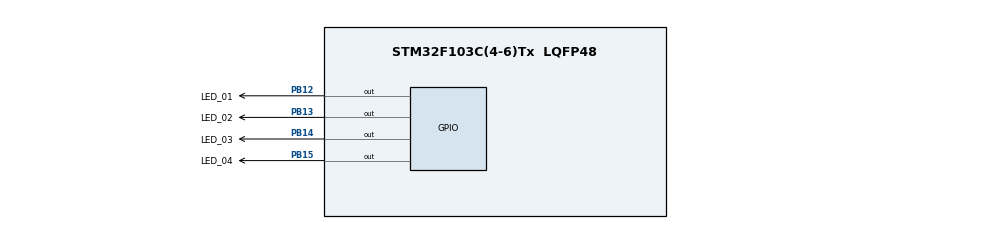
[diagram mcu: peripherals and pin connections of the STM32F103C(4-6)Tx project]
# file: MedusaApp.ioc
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Mcu.Family=STM32F1
Mcu.Name=STM32F103C(4-6)Tx
Mcu.Package=LQFP48
NVIC.PriorityGroup=NVIC_PRIORITYGROUP_4
NVIC.TIM1_UP_IRQn=true\:0\:0\:false\:false\:true\:true\:true
PA13.Mode=Serial_Wire
PA13.Signal=SYS_JTMS-SWDIO
PA14.Mode=Serial_Wire
PA14.Signal=SYS_JTCK-SWCLK
PB12.GPIO_Label=LED_01
PB12.Signal=GPIO_Output
PB13.GPIO_Label=LED_02
PB13.Signal=GPIO_Output
PB14.GPIO_Label=LED_03
PB14.Signal=GPIO_Output
PB15.GPIO_Label=LED_04
PB15.Signal=GPIO_Output
PC14-OSC32_IN.Mode=LSE-External-Oscillator
PC14-OSC32_IN.Signal=RCC_OSC32_IN
PC15-OSC32_OUT.Mode=LSE-External-Oscillator
PC15-OSC32_OUT.Signal=RCC_OSC32_OUT
ProjectManager.HeapSize=0x200
ProjectManager.StackSize=0x400
ProjectManager.TargetToolchain=STM32CubeIDE
RCC.APB1Freq_Value=8000000
RCC.APB2Freq_Value=8000000
TIM1.AutoReloadPreload=TIM_AUTORELOAD_PRELOAD_ENABLE
TIM1.Period=800
TIM1.Prescaler=1000
TIM1.TIM_MasterOutputTrigger=TIM_TRGO_UPDATE
VP_TIM1_VS_ClockSourceINT.Mode=Internal
board=custom

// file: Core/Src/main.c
/* USER CODE BEGIN Header */
/**
  ******************************************************************************
  * @file           : main.c
  * @brief          : Main program body
  ******************************************************************************
  * @attention
  *
  * <h2><center>&copy; Copyright (c) 2021 STMicroelectronics.
  * All rights reserved.</center></h2>
  *
  * This software component is licensed by ST under BSD 3-Clause license,
  * the "License"; You may not use this file except in compliance with the
  * License. You may obtain a copy of the License at:
  *                        opensource.org/licenses/BSD-3-Clause
  *
  * written date: 04/06/2021
  * revision number: SV 1.001
  ******************************************************************************
  */
/* USER CODE END Header */
#include "main.h"

TIM_HandleTypeDef htim1;

void SystemClock_Config(void);
static void MX_GPIO_Init(void);
static void MX_TIM1_Init(void);

int main(void)
{

  /* MCU Configuration--------------------------------------------------------*/

  /* Reset of all peripherals, Initializes the Flash interface and the Systick. */
  HAL_Init();

  /* Configure the system clock */
  SystemClock_Config();

  /* Initialize all configured peripherals */
  MX_GPIO_Init();
  MX_TIM1_Init();

  /* USER CODE BEGIN 2 */
  HAL_TIM_Base_Start_IT(&htim1);
  /* USER CODE END 2 */

  /* Infinite loop */
  /* USER CODE BEGIN WHILE */
  while (1)
  {
	  HAL_GPIO_TogglePin(LED_01_GPIO_Port, LED_01_Pin);
	  HAL_Delay(100);
    /* USER CODE END WHILE */

  }
}

void SystemClock_Config(void)
{
  RCC_OscInitTypeDef RCC_OscInitStruct = {0};
  RCC_ClkInitTypeDef RCC_ClkInitStruct = {0};

  /** Initializes the RCC Oscillators according to the specified parameters
  * in the RCC_OscInitTypeDef structure.
  */
  RCC_OscInitStruct.OscillatorType = RCC_OSCILLATORTYPE_HSI;
  RCC_OscInitStruct.HSIState = RCC_HSI_ON;
  RCC_OscInitStruct.HSICalibrationValue = RCC_HSICALIBRATION_DEFAULT;
  RCC_OscInitStruct.PLL.PLLState = RCC_PLL_NONE;
  if (HAL_RCC_OscConfig(&RCC_OscInitStruct) != HAL_OK)
  {
    Error_Handler();
  }
  /** Initializes the CPU, AHB and APB buses clocks
  */
  RCC_ClkInitStruct.ClockType = RCC_CLOCKTYPE_HCLK|RCC_CLOCKTYPE_SYSCLK
                              |RCC_CLOCKTYPE_PCLK1|RCC_CLOCKTYPE_PCLK2;
  RCC_ClkInitStruct.SYSCLKSource = RCC_SYSCLKSOURCE_HSI;
  RCC_ClkInitStruct.AHBCLKDivider = RCC_SYSCLK_DIV1;
  RCC_ClkInitStruct.APB1CLKDivider = RCC_HCLK_DIV1;
  RCC_ClkInitStruct.APB2CLKDivider = RCC_HCLK_DIV1;

  if (HAL_RCC_ClockConfig(&RCC_ClkInitStruct, FLASH_LATENCY_0) != HAL_OK)
  {
    Error_Handler();
  }
}

static void MX_TIM1_Init(void)
{

  TIM_ClockConfigTypeDef sClockSourceConfig = {0};
  TIM_MasterConfigTypeDef sMasterConfig = {0};

  htim1.Instance = TIM1;
  htim1.Init.Prescaler = 1000;
  htim1.Init.CounterMode = TIM_COUNTERMODE_UP;
  htim1.Init.Period = 800;
  htim1.Init.ClockDivision = TIM_CLOCKDIVISION_DIV1;
  htim1.Init.RepetitionCounter = 0;
  htim1.Init.AutoReloadPreload = TIM_AUTORELOAD_PRELOAD_ENABLE;
  if (HAL_TIM_Base_Init(&htim1) != HAL_OK)
  {
    Error_Handler();
  }
  sClockSourceConfig.ClockSource = TIM_CLOCKSOURCE_INTERNAL;
  if (HAL_TIM_ConfigClockSource(&htim1, &sClockSourceConfig) != HAL_OK)
  {
    Error_Handler();
  }
  sMasterConfig.MasterOutputTrigger = TIM_TRGO_UPDATE;
  sMasterConfig.MasterSlaveMode = TIM_MASTERSLAVEMODE_DISABLE;
  if (HAL_TIMEx_MasterConfigSynchronization(&htim1, &sMasterConfig) != HAL_OK)
  {
    Error_Handler();
  }

}

static void MX_GPIO_Init(void)
{
  GPIO_InitTypeDef GPIO_InitStruct = {0};

  /* GPIO Ports Clock Enable */
  __HAL_RCC_GPIOC_CLK_ENABLE();
  __HAL_RCC_GPIOB_CLK_ENABLE();
  __HAL_RCC_GPIOA_CLK_ENABLE();

  /*Configure GPIO pin Output Level */
  HAL_GPIO_WritePin(GPIOB, LED_01_Pin|LED_02_Pin|LED_03_Pin|LED_04_Pin, GPIO_PIN_RESET);

  /*Configure GPIO pins : LED_01_Pin LED_02_Pin LED_03_Pin LED_04_Pin */
  GPIO_InitStruct.Pin = LED_01_Pin|LED_02_Pin|LED_03_Pin|LED_04_Pin;
  GPIO_InitStruct.Mode = GPIO_MODE_OUTPUT_PP;
  GPIO_InitStruct.Pull = GPIO_NOPULL;
  GPIO_InitStruct.Speed = GPIO_SPEED_FREQ_LOW;
  HAL_GPIO_Init(GPIOB, &GPIO_InitStruct);

}

/* USER CODE BEGIN 4 */
void HAL_TIM_PeriodElapsedCallback(TIM_HandleTypeDef* htim)
{
    HAL_GPIO_TogglePin(LED_04_GPIO_Port, LED_04_Pin);
}

/* USER CODE END 4 */

void Error_Handler(void)
{
  __disable_irq();
  while (1)
  {
  }
}

/************************ (C) COPYRIGHT STMicroelectronics *****END OF FILE****/
